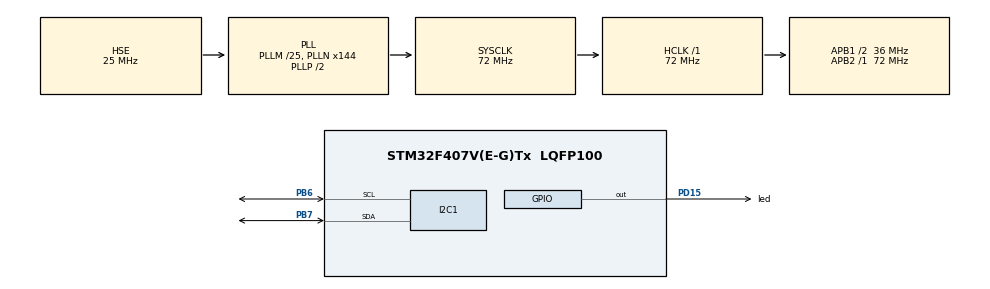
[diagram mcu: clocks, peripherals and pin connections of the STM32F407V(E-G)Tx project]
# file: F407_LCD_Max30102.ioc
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Mcu.Family=STM32F4
Mcu.Name=STM32F407V(E-G)Tx
Mcu.Package=LQFP100
NVIC.PriorityGroup=NVIC_PRIORITYGROUP_4
PA13.Mode=Serial_Wire
PA13.Signal=SYS_JTMS-SWDIO
PA14.Mode=Serial_Wire
PA14.Signal=SYS_JTCK-SWCLK
PB6.Mode=I2C
PB6.Signal=I2C1_SCL
PB7.Mode=I2C
PB7.Signal=I2C1_SDA
PD15.GPIO_Label=led
PD15.PinState=GPIO_PIN_SET
PD15.Signal=GPIO_Output
PH0-OSC_IN.Mode=HSE-External-Oscillator
PH0-OSC_IN.Signal=RCC_OSC_IN
PH1-OSC_OUT.Mode=HSE-External-Oscillator
PH1-OSC_OUT.Signal=RCC_OSC_OUT
ProjectManager.HeapSize=0x200
ProjectManager.StackSize=0x400
ProjectManager.TargetToolchain=MDK-ARM V5
RCC.48MHZClocksFreq_Value=36000000
RCC.AHBFreq_Value=72000000
RCC.APB1CLKDivider=RCC_HCLK_DIV2
RCC.APB1Freq_Value=36000000
RCC.APB1TimFreq_Value=72000000
RCC.APB2Freq_Value=72000000
RCC.APB2TimFreq_Value=72000000
RCC.CortexFreq_Value=72000000
RCC.HCLKFreq_Value=72000000
RCC.HSE_VALUE=25000000
RCC.HSI_VALUE=16000000
RCC.LSE_VALUE=32768
RCC.PLLM=25
RCC.PLLN=144
RCC.PLLSourceVirtual=RCC_PLLSOURCE_HSE
RCC.SYSCLKFreq_VALUE=72000000
RCC.SYSCLKSource=RCC_SYSCLKSOURCE_PLLCLK
RCC.VCOOutputFreq_Value=144000000
TIM4.Period=999
TIM4.Prescaler=72
VP_TIM4_VS_ClockSourceINT.Mode=Internal
board=custom

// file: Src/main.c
/* USER CODE BEGIN Header */
/**
  ******************************************************************************
  * @file           : main.c
  * @brief          : Main program body
  ******************************************************************************
  * @attention
  *
  * <h2><center>&copy; Copyright (c) 2025 STMicroelectronics.
  * All rights reserved.</center></h2>
  *
  * This software component is licensed by ST under BSD 3-Clause license,
  * the "License"; You may not use this file except in compliance with the
  * License. You may obtain a copy of the License at:
  *                        opensource.org/licenses/BSD-3-Clause
  *
  ******************************************************************************
  */
/* USER CODE END Header */

#include "main.h"

/* USER CODE BEGIN Includes */
#include "lcd_16x2.h"
/* USER CODE END Includes */

I2C_HandleTypeDef hi2c1;

TIM_HandleTypeDef htim4;

void SystemClock_Config(void);
static void MX_GPIO_Init(void);
static void MX_I2C1_Init(void);
static void MX_TIM4_Init(void);

int main(void)
{

  /* MCU Configuration--------------------------------------------------------*/

  /* Reset of all peripherals, Initializes the Flash interface and the Systick. */
  HAL_Init();

  /* USER CODE BEGIN Init */
	Lcd_Init();
  /* USER CODE END Init */

  /* Configure the system clock */
  SystemClock_Config();

  /* Initialize all configured peripherals */
  MX_GPIO_Init();
  MX_I2C1_Init();
  MX_TIM4_Init();
  /* USER CODE BEGIN 2 */
	Lcd_clear_display();
	Lcd_gotoxy(3,1);
	Lcd_write_string("Hung OK");
	HAL_Delay(1000);
  /* USER CODE END 2 */

  /* Infinite loop */
  while (1)
  {

    /* USER CODE BEGIN 3 */
		Lcd_gotoxy(3,1);
		Lcd_write_string("TEST_LCD");
		Lcd_gotoxy(3,0);
		Lcd_write_int(-2568);

		HAL_GPIO_TogglePin(led_GPIO_Port, led_Pin);
		HAL_Delay(200);
  }
  /* USER CODE END 3 */
}

void SystemClock_Config(void)
{
  RCC_OscInitTypeDef RCC_OscInitStruct = {0};
  RCC_ClkInitTypeDef RCC_ClkInitStruct = {0};

  /** Configure the main internal regulator output voltage
  */
  __HAL_RCC_PWR_CLK_ENABLE();
  __HAL_PWR_VOLTAGESCALING_CONFIG(PWR_REGULATOR_VOLTAGE_SCALE1);
  /** Initializes the CPU, AHB and APB busses clocks
  */
  RCC_OscInitStruct.OscillatorType = RCC_OSCILLATORTYPE_HSE;
  RCC_OscInitStruct.HSEState = RCC_HSE_ON;
  RCC_OscInitStruct.PLL.PLLState = RCC_PLL_ON;
  RCC_OscInitStruct.PLL.PLLSource = RCC_PLLSOURCE_HSE;
  RCC_OscInitStruct.PLL.PLLM = 25;
  RCC_OscInitStruct.PLL.PLLN = 144;
  RCC_OscInitStruct.PLL.PLLP = RCC_PLLP_DIV2;
  RCC_OscInitStruct.PLL.PLLQ = 4;
  if (HAL_RCC_OscConfig(&RCC_OscInitStruct) != HAL_OK)
  {
    Error_Handler();
  }
  /** Initializes the CPU, AHB and APB busses clocks
  */
  RCC_ClkInitStruct.ClockType = RCC_CLOCKTYPE_HCLK|RCC_CLOCKTYPE_SYSCLK
                              |RCC_CLOCKTYPE_PCLK1|RCC_CLOCKTYPE_PCLK2;
  RCC_ClkInitStruct.SYSCLKSource = RCC_SYSCLKSOURCE_PLLCLK;
  RCC_ClkInitStruct.AHBCLKDivider = RCC_SYSCLK_DIV1;
  RCC_ClkInitStruct.APB1CLKDivider = RCC_HCLK_DIV2;
  RCC_ClkInitStruct.APB2CLKDivider = RCC_HCLK_DIV1;

  if (HAL_RCC_ClockConfig(&RCC_ClkInitStruct, FLASH_LATENCY_2) != HAL_OK)
  {
    Error_Handler();
  }
}

static void MX_I2C1_Init(void)
{

  hi2c1.Instance = I2C1;
  hi2c1.Init.ClockSpeed = 100000;
  hi2c1.Init.DutyCycle = I2C_DUTYCYCLE_2;
  hi2c1.Init.OwnAddress1 = 0;
  hi2c1.Init.AddressingMode = I2C_ADDRESSINGMODE_7BIT;
  hi2c1.Init.DualAddressMode = I2C_DUALADDRESS_DISABLE;
  hi2c1.Init.OwnAddress2 = 0;
  hi2c1.Init.GeneralCallMode = I2C_GENERALCALL_DISABLE;
  hi2c1.Init.NoStretchMode = I2C_NOSTRETCH_DISABLE;
  if (HAL_I2C_Init(&hi2c1) != HAL_OK)
  {
    Error_Handler();
  }

}

static void MX_TIM4_Init(void)
{

  TIM_ClockConfigTypeDef sClockSourceConfig = {0};
  TIM_MasterConfigTypeDef sMasterConfig = {0};

  htim4.Instance = TIM4;
  htim4.Init.Prescaler = 72;
  htim4.Init.CounterMode = TIM_COUNTERMODE_UP;
  htim4.Init.Period = 999;
  htim4.Init.ClockDivision = TIM_CLOCKDIVISION_DIV1;
  htim4.Init.AutoReloadPreload = TIM_AUTORELOAD_PRELOAD_DISABLE;
  if (HAL_TIM_Base_Init(&htim4) != HAL_OK)
  {
    Error_Handler();
  }
  sClockSourceConfig.ClockSource = TIM_CLOCKSOURCE_INTERNAL;
  if (HAL_TIM_ConfigClockSource(&htim4, &sClockSourceConfig) != HAL_OK)
  {
    Error_Handler();
  }
  sMasterConfig.MasterOutputTrigger = TIM_TRGO_RESET;
  sMasterConfig.MasterSlaveMode = TIM_MASTERSLAVEMODE_DISABLE;
  if (HAL_TIMEx_MasterConfigSynchronization(&htim4, &sMasterConfig) != HAL_OK)
  {
    Error_Handler();
  }

}

static void MX_GPIO_Init(void)
{
  GPIO_InitTypeDef GPIO_InitStruct = {0};

  /* GPIO Ports Clock Enable */
  __HAL_RCC_GPIOH_CLK_ENABLE();
  __HAL_RCC_GPIOD_CLK_ENABLE();
  __HAL_RCC_GPIOA_CLK_ENABLE();
  __HAL_RCC_GPIOB_CLK_ENABLE();

  /*Configure GPIO pin Output Level */
  HAL_GPIO_WritePin(led_GPIO_Port, led_Pin, GPIO_PIN_SET);

  /*Configure GPIO pin : led_Pin */
  GPIO_InitStruct.Pin = led_Pin;
  GPIO_InitStruct.Mode = GPIO_MODE_OUTPUT_PP;
  GPIO_InitStruct.Pull = GPIO_NOPULL;
  GPIO_InitStruct.Speed = GPIO_SPEED_FREQ_LOW;
  HAL_GPIO_Init(led_GPIO_Port, &GPIO_InitStruct);

}

void Error_Handler(void)
{
}

/************************ (C) COPYRIGHT STMicroelectronics *****END OF FILE****/
